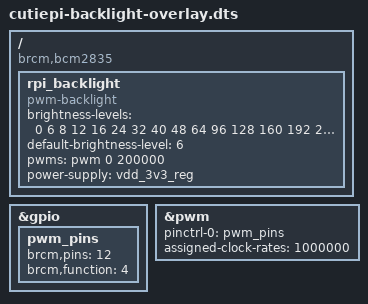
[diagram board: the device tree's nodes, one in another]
/dts-v1/;
/plugin/;

/ {
    compatible = "brcm,bcm2835", "bcrm,bcm2711";

    fragment@0 {
        target = <&gpio>;
        __overlay__ {
            pwm_pins: pwm_pins {
                brcm,pins = <12>;
                brcm,function = <4>; // ALT0
            };
        };
    };

    fragment@1 {
        target = <&pwm>;
        frag1: __overlay__ {
            pinctrl-names = "default";
            pinctrl-0 = <&pwm_pins>;
            assigned-clock-rates = <1000000>;
            status = "okay";
        };
    };

    fragment@2 {
        target-path = "/";
        __overlay__ {
            rpi_backlight: rpi_backlight {
                compatible = "pwm-backlight";
                brightness-levels = <0 6 8 12 16 24 32 40 48 64 96 128 160 192 224 255>;
                default-brightness-level = <6>;
                pwms = <&pwm 0 200000>;
                power-supply = <&vdd_3v3_reg>;
                status = "okay";
            };
        };
    };

    __overrides__ {
        pin   = <&pwm_pins>,"brcm,pins:0";
        func  = <&pwm_pins>,"brcm,function:0";
        clock = <&frag1>,"assigned-clock-rates:0";
    };
};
